AUTOSAR XML (schema 4-3-0)
package /ComponentTypes
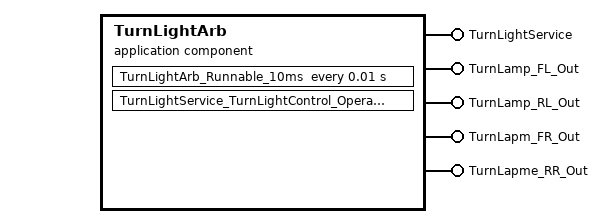
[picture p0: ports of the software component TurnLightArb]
  application sw component type TurnLightArb
    5 x provide port:
      TurnLightService: server-com-spec{operation=TurnLightControl_Operation, queue-length=1}, provided-interface=TurnLightService
      TurnLamp_FL_Out: nonqueued-sender-com-spec{data-element=u8_Signal, init-value=0}, provided-interface=TurnLamp_FL_Out
      TurnLamp_RL_Out: nonqueued-sender-com-spec{data-element=u8_Signal, init-value=0}, provided-interface=TurnLamp_RL_Out
      TurnLapm_FR_Out: nonqueued-sender-com-spec{data-element=u8_Signal, init-value=0}, provided-interface=TurnLapm_FR_Out
      TurnLapme_RR_Out: nonqueued-sender-com-spec{data-element=u8_Signal, init-value=0}, provided-interface=TurnLapme_RR_Out
    behavior TurnLightArb_InternalBehavior
      operation invoked event OIT_TurnLightService_TurnLightControl_Operation_TurnLightService_TurnLightControl_Operation: start-on-event=TurnLightService_TurnLightControl_Operation, operation=TurnLightService.TurnLightControl_Operation
      timing event TMT_TurnLightArb_Runnable_10ms: start-on-event=TurnLightArb_Runnable_10ms, period=0.01
      runnable TurnLightArb_Runnable_10ms: minimum-start-interval=0.01
        data-send-points:
          4 x access:
            SEND_TurnLamp_FL_Out_u8_Signal: accessed-variable=TurnLamp_FL_Out.u8_Signal
            SEND_TurnLamp_RL_Out_u8_Signal: accessed-variable=TurnLamp_RL_Out.u8_Signal
            SEND_TurnLapm_FR_Out_u8_Signal: accessed-variable=TurnLapm_FR_Out.u8_Signal
            SEND_TurnLapme_RR_Out_u8_Signal: accessed-variable=TurnLapme_RR_Out.u8_Signal
      runnable TurnLightService_TurnLightControl_Operation: can-be-invoked-concurrently=true
  swc implementation TurnLightArb_Implementation: behavior=TurnLightArb_InternalBehavior
